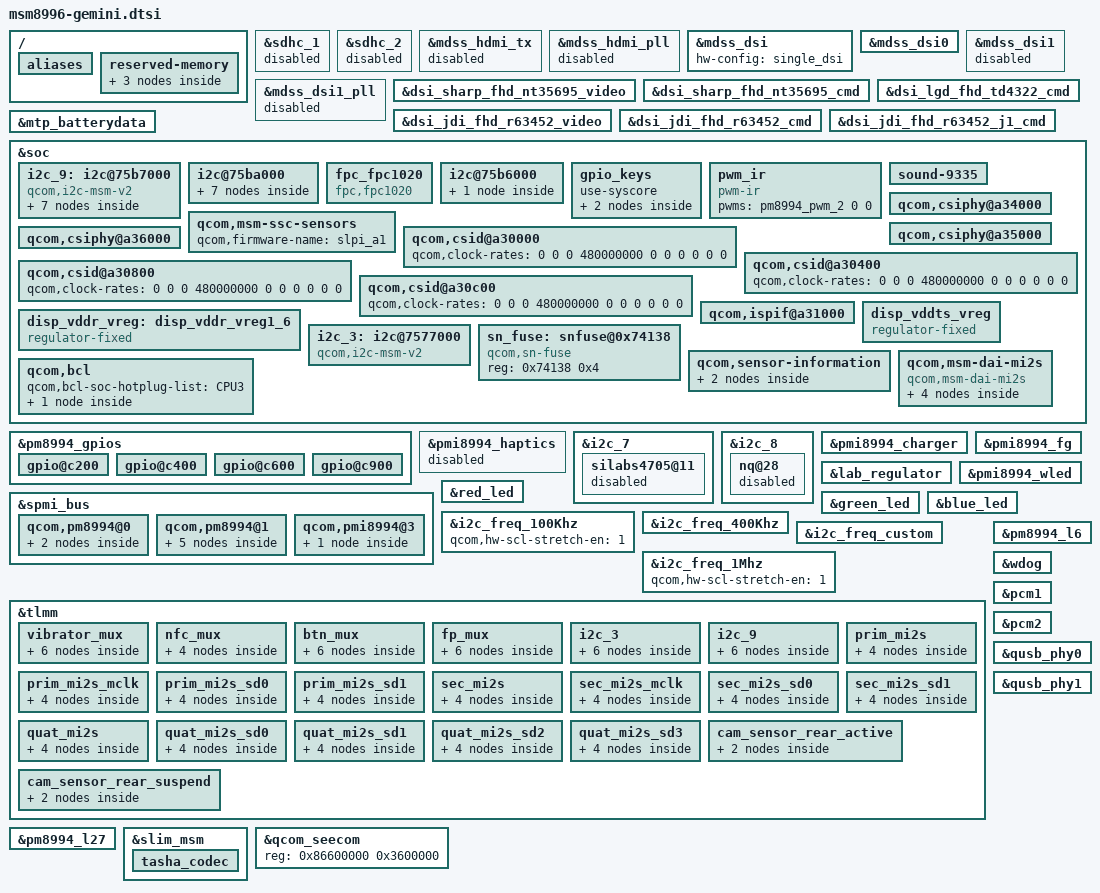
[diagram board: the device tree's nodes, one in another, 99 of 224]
/* Copyright (c) 2015, The Linux Foundation. All rights reserved.
 * Copyright (C) 2016 XiaoMi, Inc.
 *
 * This program is free software; you can redistribute it and/or modify
 * it under the terms of the GNU General Public License version 2 and
 * only version 2 as published by the Free Software Foundation.
 *
 * This program is distributed in the hope that it will be useful,
 * but WITHOUT ANY WARRANTY; without even the implied warranty of
 * MERCHANTABILITY or FITNESS FOR A PARTICULAR PURPOSE.  See the
 * GNU General Public License for more details.
 */

#include "msm8996-mtp.dtsi"
#include "msm8996-camera-sensor-mtp.dtsi"
#include "msm8996-camera-sensor-gemini.dtsi"

// msm8996-mtp.dtsi start
&sdhc_1 {
	status = "disabled";
};

&sdhc_2 {
	status = "disabled";
};

&mdss_hdmi_tx {
	status = "disabled";
};

&mdss_hdmi_pll {
	status = "disabled";
};

#include "msm8996-mdss-panels-gemini.dtsi"

&mdss_dsi {
	hw-config = "single_dsi";
};

&mdss_dsi0 {
	vddr-supply = <&disp_vddr_vreg>;
	qcom,dsi-pref-prim-pan = <&dsi_sharp_fhd_nt35695_video>;
	qcom,platform-enable-gpio = <&tlmm 47 0>;
	qcom,platform-bklight-en-gpio = <&tlmm 48 0>;
};

&mdss_dsi1 {
	status = "disabled";
};

&mdss_dsi1_pll {
	status = "disabled";
};

&dsi_sharp_fhd_nt35695_video {
	qcom,mdss-dsi-bl-pmic-control-type = "bl_ctrl_wled";
	qcom,mdss-dsi-bl-min-level = <1>;
	qcom,mdss-dsi-bl-max-level = <4095>;
	qcom,cont-splash-enabled;
	qcom,panel-supply-entries = <&dsi_panel_pwr_supply>;
};

&dsi_sharp_fhd_nt35695_cmd {
	qcom,mdss-dsi-bl-pmic-control-type = "bl_ctrl_wled";
	qcom,mdss-dsi-bl-min-level = <1>;
	qcom,mdss-dsi-bl-max-level = <4095>;
	qcom,cont-splash-enabled;
	qcom,panel-supply-entries = <&dsi_panel_pwr_supply>;
};

&dsi_lgd_fhd_td4322_cmd {
	qcom,mdss-dsi-bl-pmic-control-type = "bl_ctrl_wled";
	qcom,mdss-dsi-bl-min-level = <1>;
	qcom,mdss-dsi-bl-max-level = <4095>;
	qcom,panel-supply-entries = <&dsi_panel_pwr_supply>;
};

&dsi_jdi_fhd_r63452_video {
	qcom,mdss-dsi-bl-pmic-control-type = "bl_ctrl_wled";
	qcom,mdss-dsi-bl-min-level = <1>;
	qcom,mdss-dsi-bl-max-level = <4095>;
	qcom,cont-splash-enabled;
	qcom,panel-supply-entries = <&dsi_panel_pwr_supply>;
};

&dsi_jdi_fhd_r63452_cmd {
	qcom,mdss-dsi-bl-pmic-control-type = "bl_ctrl_wled";
	qcom,mdss-dsi-bl-min-level = <1>;
	qcom,mdss-dsi-bl-max-level = <4095>;
	qcom,cont-splash-enabled;
	qcom,panel-supply-entries = <&dsi_panel_pwr_supply>;
};

&dsi_jdi_fhd_r63452_j1_cmd {
	qcom,mdss-dsi-bl-pmic-control-type = "bl_ctrl_wled";
	qcom,mdss-dsi-bl-min-level = <1>;
	qcom,mdss-dsi-bl-max-level = <4095>;
	qcom,panel-supply-entries = <&dsi_panel_pwr_supply>;
};

&mtp_batterydata {
	#include "batterydata-a1-atl-3000mah.dtsi"
	#include "batterydata-a1-sdi-3000mah.dtsi"
};

&soc {
	i2c@75b7000 {
		status = "ok";

		tfa98xx@34 {
			reg = <0x34>;
			compatible = "nxp,tfa9890";
			nxp,reset-gpio = <&pmi8994_gpios 2 0>;
		};

		drv2604@5a {
			compatible = "vibrator,drv2604";
			reg = <0x5a>;
			qcom,vibrator-gpio = <&tlmm 93 0x00>;
			pinctrl-names = "vibrator_active","vibrator_suspend";
			pinctrl-0 = <&vibrator_active>;
			pinctrl-1 = <&vibrator_suspend>;
		};

		lp5562@30 {
			compatible = "ti,lp5562";
			reg = <0x30>;
			enable-gpio = <&pm8994_gpios 7 1>;
			clock-mode = /bits/8 <2>;
			label = "button-backlight";
			chan0 {
				chan-name = "button-backlight";
				led-cur = /bits/ 8 <0x32>;
				max-cur = /bits/ 8 <0xC8>;
			};
			chan1 {
				chan-name = "button-backlight1";
				led-cur = /bits/ 8 <0x32>;
				max-cur = /bits/ 8 <0xC8>;
			};
		};

		tusb320l@67 {
			compatible = "ti,tusb320l";
			reg = <0x67>;
		};

		tusb320l@47 {
			compatible = "ti,tusb320l";
			reg = <0x47>;
		};
	};

	i2c@75ba000 {
		/delete-node/ synaptics@20;

		synaptics_dsi_i2c@20 {
			compatible = "synaptics,dsx-i2c";
			reg = <0x20>;
			interrupt-parent = <&tlmm>;
			interrupts = <125 0x2008>;
			vdd-supply = <&pm8994_l6>;
			lab-supply = <&lab_regulator>;
			ibb-supply = <&ibb_regulator>;
			disp-supply = <&pm8994_l14>;
			avdd-supply = <&disp_vddts_vreg>;
			synaptics,pwr-reg-name = "vdd";
			synaptics,lab-reg-name = "lab";
			synaptics,ibb-reg-name = "ibb";
			synaptics,disp-reg-name = "disp";
			synaptics,bus-reg-name = "avdd";
			synaptics,ub-i2c-addr = <0x20>;
			pinctrl-names = "pmx_ts_active", "pmx_ts_suspend";
			pinctrl-0 = <&ts_active>;
			pinctrl-1 = <&ts_suspend>;
			synaptics,mdss-dsi-reset = <&tlmm 8 0>;
			synaptics,reset-gpio = <&tlmm 89 0x00>;
			synaptics,irq-gpio = <&tlmm 125 0x2008>;
			synaptics,reset-gpio-name = "dsx_reset";
			synaptics,irq-gpio-name = "dsx_irq";
			synaptics,irq-on-state = <0>;
			synaptics,irq-flags = <0x2008>; /* IRQF_ONESHOT | IRQF_TRIGGER_LOW */
			synaptics,power-delay-ms = <5>;
			synaptics,reset-delay-ms = <200>;
			synaptics,reset-active-ms = <5>;
			synaptics,power-on-state = <1>;
			synaptics,reset-on-state = <0>;
			synaptics,mdss-reset-state = <1>;
			synaptics,cap-button-codes = <158 139 102>;
			clock-names = "iface_clk", "core_clk";
			clocks = <&clock_gcc clk_gcc_blsp2_ahb_clk>,
				<&clock_gcc clk_gcc_blsp2_qup6_i2c_apps_clk>;
			synaptics,guest-serialization-as-lockdown;
			synaptics,tp-id-byte = /bits/ 8 <0>;
		};

		atmel_mxt_ts_641t@4a {
			compatible = "atmel,mxt-ts";
			reg = <0x4a>;
			interrupt-parent = <&tlmm>;
			interrupts = <125 0x2008>;
			vddio-supply = <&pm8994_l6>;
			vdd-supply = <&disp_vddts_vreg>;
			/* pins used by touchscreen */
			pinctrl-names = "pmx_ts_active","pmx_ts_suspend";
			pinctrl-0 = <&ts_active>;
			pinctrl-1 = <&ts_suspend>;
			atmel,reset-gpio = <&tlmm 89 0x00>;
			atmel,irq-gpio = <&tlmm 125 0x2008>;
			atmel,mxt-fw-name = "mXT641T30AC.fw";
			atmel,config-array-size = <5>;
			atmel,default-config = <0>;
			atmel,default-panel-id = <0x31>;
			atmel,irqflags = <0x2008>;
			atmel,gpio-mask = <0xC>;
			atmel,cfg_1 {
				atmel,family-id = <0xA4>;
				atmel,variant-id = <0x2F>;
				atmel,version = <0x30>;
				atmel,build = <0xAC>;
				atmel,rev-id = <0x32>;
				atmel,mxt-cfg-name = "mxt_641t_sharp_config.fw";
				atmel,vendor-id = <0x0C>;
				atmel,panel-id = <0x38>; /* Sharp id = 0x38 */
				atmel,key-codes = <158 139 102>;
				atmel,selfintthr-stylus = <0>;
				atmel,t71-tchthr-pos = <22>;
				atmel,self-chgtime-min = <0>;
				atmel,self-chgtime-max = <0>;
				atmel,mult-intthr-sensitive = <0>;
				atmel,mult-intthr-not-sensitive = <17>;
				atmel,atchthr-sensitive = <6>;
				atmel,mult-tchthr-sensitive = <0x0f>;
				atmel,mult-tchthr-not-sensitive = <0>;
				atmel,wake-up-self-adcx = <16>;
				atmel,atchratio = <33>;
				atmel,xycfg = <0>;
				atmel,xsize = <0x07>;
				atmel,xrange-lsb = <0x08>;
				atmel,xrange-msb = <0x02>;
				atmel,tchhyst = <0x05>;
				atmel,intthrhyst = <0>;
				atmel,xtchthr = <0x0f>;
				atmel,xtchhyst = <0x05>;
				atmel,intthrx = <0>;
				atmel,ytchthr = <0x0f>;
				atmel,ytchhyst = <0x05>;
				atmel,intthry = <0>;
			};
			atmel,cfg_2 {
				atmel,family-id = <0xA4>;
				atmel,variant-id = <0x2F>;
				atmel,version = <0x30>;
				atmel,build = <0xAC>;
				atmel,rev-id = <0x32>;
				atmel,mxt-cfg-name = "mxt_641t_sharp_config.fw";
				atmel,vendor-id = <0x0C>;
				atmel,panel-id = <0x31>; /* Biel id = 0x31 */
				atmel,key-codes = <158 139 102>;
				atmel,selfintthr-stylus = <0>;
				atmel,t71-tchthr-pos = <22>;
				atmel,self-chgtime-min = <0>;
				atmel,self-chgtime-max = <0>;
				atmel,mult-intthr-sensitive = <0>;
				atmel,mult-intthr-not-sensitive = <17>;
				atmel,atchthr-sensitive = <6>;
				atmel,mult-tchthr-sensitive = <0x0f>;
				atmel,mult-tchthr-not-sensitive = <0>;
				atmel,wake-up-self-adcx = <16>;
				atmel,atchratio = <33>;
				atmel,xycfg = <0>;
				atmel,xsize = <0x07>;
				atmel,xrange-lsb = <0x08>;
				atmel,xrange-msb = <0x02>;
				atmel,tchhyst = <0x05>;
				atmel,intthrhyst = <0>;
				atmel,xtchthr = <0x0f>;
				atmel,xtchhyst = <0x05>;
				atmel,intthrx = <0>;
				atmel,ytchthr = <0x0f>;
				atmel,ytchhyst = <0x05>;
				atmel,intthry = <0>;
			};
			atmel,cfg_3 {
				atmel,family-id = <0xA4>;
				atmel,variant-id = <0x2F>;
				atmel,version = <0x30>;
				atmel,build = <0xAC>;
				atmel,rev-id = <0x32>;
				atmel,mxt-cfg-name = "mxt_641t_sharp_config.fw";
				atmel,vendor-id = <0x0C>;
				atmel,panel-id = <0x51>; /* WA: Incorrect lockdown */
				atmel,key-codes = <158 139 102>;
				atmel,selfintthr-stylus = <0>;
				atmel,t71-tchthr-pos = <22>;
				atmel,self-chgtime-min = <0>;
				atmel,self-chgtime-max = <0>;
				atmel,mult-intthr-sensitive = <0>;
				atmel,mult-intthr-not-sensitive = <17>;
				atmel,atchthr-sensitive = <6>;
				atmel,mult-tchthr-sensitive = <0x0f>;
				atmel,mult-tchthr-not-sensitive = <0>;
				atmel,wake-up-self-adcx = <16>;
				atmel,atchratio = <33>;
				atmel,xycfg = <0>;
				atmel,xsize = <0x07>;
				atmel,xrange-lsb = <0x08>;
				atmel,xrange-msb = <0x02>;
				atmel,tchhyst = <0x05>;
				atmel,intthrhyst = <0>;
				atmel,xtchthr = <0x0f>;
				atmel,xtchhyst = <0x05>;
				atmel,intthrx = <0>;
				atmel,ytchthr = <0x0f>;
				atmel,ytchhyst = <0x05>;
				atmel,intthry = <0>;
			};
			atmel,cfg_4 {
				atmel,family-id = <0xA4>;
				atmel,variant-id = <0x2F>;
				atmel,version = <0x30>;
				atmel,build = <0xAC>;
				atmel,rev-id = <0x32>;
				atmel,mxt-cfg-name = "mxt_641t_sharp_config.fw";
				atmel,vendor-id = <0x0C>;
				atmel,panel-id = <0x52>; /* WA: Incorrect lockdown */
				atmel,key-codes = <158 139 102>;
				atmel,selfintthr-stylus = <0>;
				atmel,t71-tchthr-pos = <22>;
				atmel,self-chgtime-min = <0>;
				atmel,self-chgtime-max = <0>;
				atmel,mult-intthr-sensitive = <0>;
				atmel,mult-intthr-not-sensitive = <17>;
				atmel,atchthr-sensitive = <6>;
				atmel,mult-tchthr-sensitive = <0x0f>;
				atmel,mult-tchthr-not-sensitive = <0>;
				atmel,wake-up-self-adcx = <16>;
				atmel,atchratio = <33>;
				atmel,xycfg = <0>;
				atmel,xsize = <0x07>;
				atmel,xrange-lsb = <0x08>;
				atmel,xrange-msb = <0x02>;
				atmel,tchhyst = <0x05>;
				atmel,intthrhyst = <0>;
				atmel,xtchthr = <0x0f>;
				atmel,xtchhyst = <0x05>;
				atmel,intthrx = <0>;
				atmel,ytchthr = <0x0f>;
				atmel,ytchhyst = <0x05>;
				atmel,intthry = <0>;
			};
			atmel,cfg_5 {
				atmel,family-id = <0xA4>;
				atmel,variant-id = <0x2F>;
				atmel,version = <0x30>;
				atmel,build = <0xAC>;
				atmel,rev-id = <0x32>;
				atmel,mxt-cfg-name = "mxt_641t_sharp_config.fw";
				atmel,vendor-id = <0x0C>;
				atmel,panel-id = <0x32>; /* lens id = 0x32 */
				atmel,key-codes = <158 139 102>;
				atmel,selfintthr-stylus = <0>;
				atmel,t71-tchthr-pos = <22>;
				atmel,self-chgtime-min = <0>;
				atmel,self-chgtime-max = <0>;
				atmel,mult-intthr-sensitive = <0>;
				atmel,mult-intthr-not-sensitive = <17>;
				atmel,atchthr-sensitive = <6>;
				atmel,mult-tchthr-sensitive = <0x0f>;
				atmel,mult-tchthr-not-sensitive = <0>;
				atmel,wake-up-self-adcx = <16>;
				atmel,atchratio = <33>;
				atmel,xycfg = <0>;
				atmel,xsize = <0x07>;
				atmel,xrange-lsb = <0x08>;
				atmel,xrange-msb = <0x02>;
				atmel,tchhyst = <0x05>;
				atmel,intthrhyst = <0>;
				atmel,xtchthr = <0x0f>;
				atmel,xtchhyst = <0x05>;
				atmel,intthrx = <0>;
				atmel,ytchthr = <0x0f>;
				atmel,ytchhyst = <0x05>;
				atmel,intthry = <0>;
			};
		};
	};

	fpc_fpc1020 {
		compatible = "fpc,fpc1020";
		fpc,reset-gpio	= <&tlmm 50 0x00>;
		fpc,irq-gpio	= <&tlmm 121 0x2001>;
		fpc,fp-id-gpio = <&pm8994_gpios 10 0x00>;
		pinctrl-names = "pmx_fp_active", "pmx_fp_suspend";
		pinctrl-0 = <&fp_active>;
		pinctrl-1 = <&fp_suspend>;
		vcc_spi-supply	= <&pm8994_s4>;
		vdd_ana-supply	= <&pm8994_s4>;
		vdd_io-supply	= <&pm8994_s4>;
	};

	i2c@75b6000 {
		pn548 {
			compatible = "nxp,nfc-548";
			reg = <0x28>;
			nxp-nfc-548,irq-gpio = <&tlmm 9 0x00>;
			nxp-nfc-548,firm-gpio = <&tlmm 21 0x00>;
			nxp-nfc-548,ven-gpio = <&tlmm 12 0x00>;
			interrupt-parent = <&tlmm>;
			interrupts = <9 0>;
			interrupt-names = "nfc_irq";
			pinctrl-names = "pmx_nfc_active","pmx_nfc_suspend";
			pinctrl-0 = <&nfc_active>;
			pinctrl-1 = <&nfc_suspend>;
		};
	};

	gpio_keys {
		use-syscore;

		dome {
			label = "dome";
			gpios = <&tlmm 34 0x1>;
			linux,input-type = <1>;
			linux,code = <102>;
			gpio-key,wakeup;
			debounce-interval = <15>;
		};

		/delete-node/ cam_focus;

		hall_key0 {
			label = "hall_key0";
			gpios = <&tlmm 124 0x01>;
			linux,input-type = <5>;
			linux,code = <0>;
			gpio-key,wakeup;
			debounce-interval = <15>;
		};
	};

	pwm_ir {
		compatible = "pwm-ir";
		pwms = <&pm8994_pwm_2 0 0>;
	};

	sound-9335 {
		qcom,audio-routing =
			"AIF4 VI", "MCLK",
			"RX_BIAS", "MCLK",
			"MADINPUT", "MCLK",
			"hifi amp", "LINEOUT1",
			"hifi amp", "LINEOUT2",
			"AMIC1", "MIC BIAS1",
			"MIC BIAS1", "Handset Mic",
			"AMIC2", "MIC BIAS2",
			"MIC BIAS2", "Headset Mic",
			"AMIC3", "MIC BIAS4",
			"MIC BIAS4", "ANCRight Headset Mic",
			"AMIC4", "MIC BIAS4",
			"MIC BIAS4", "ANCLeft Headset Mic",
			"AMIC5", "MIC BIAS3",
			"MIC BIAS3", "Handset Mic",
			"AMIC6", "MIC BIAS4",
			"MIC BIAS4", "Analog Mic6",
			"DMIC0", "MIC BIAS1",
			"MIC BIAS1", "Digital Mic0",
			"DMIC1", "MIC BIAS1",
			"MIC BIAS1", "Digital Mic1",
			"DMIC2", "MIC BIAS3",
			"MIC BIAS3", "Digital Mic2",
			"DMIC3", "MIC BIAS3",
			"MIC BIAS3", "Digital Mic3",
			"DMIC4", "MIC BIAS4",
			"MIC BIAS4", "Digital Mic4",
			"DMIC5", "MIC BIAS4",
			"MIC BIAS4", "Digital Mic5",
			"SpkrLeft IN", "SPK1 OUT",
			"SpkrRight IN", "SPK2 OUT";

		qcom,msm-mbhc-hphl-swh = <1>;
		qcom,msm-mbhc-gnd-swh = <1>;

		/delete-property/ qcom,hdmi-audio-rx;

		asoc-cpu = <&dai_pri_auxpcm>, <&dai_sec_auxpcm>, <&dai_hdmi>,
				<&dai_pri_mi2s>, <&dai_sec_mi2s>,
				<&dai_tert_mi2s>, <&dai_quat_mi2s>,
				<&sb_0_rx>, <&sb_0_tx>, <&sb_1_rx>, <&sb_1_tx>,
				<&sb_2_rx>, <&sb_2_tx>, <&sb_3_rx>, <&sb_3_tx>,
				<&sb_4_rx>, <&sb_4_tx>, <&sb_5_tx>, <&afe_pcm_rx>,
				<&afe_pcm_tx>, <&afe_proxy_rx>, <&afe_proxy_tx>,
				<&incall_record_rx>, <&incall_record_tx>,
				<&incall_music_rx>, <&incall_music2_rx>,
				<&sb_5_rx>, <&sb_6_rx>;
		asoc-cpu-names = "msm-dai-q6-auxpcm.1", "msm-dai-q6-auxpcm.2",
				"msm-dai-q6-hdmi.8", "msm-dai-q6-mi2s.0",
				"msm-dai-q6-mi2s.1", "msm-dai-q6-mi2s.2",
				"msm-dai-q6-mi2s.3",
				"msm-dai-q6-dev.16384", "msm-dai-q6-dev.16385",
				"msm-dai-q6-dev.16386", "msm-dai-q6-dev.16387",
				"msm-dai-q6-dev.16388", "msm-dai-q6-dev.16389",
				"msm-dai-q6-dev.16390", "msm-dai-q6-dev.16391",
				"msm-dai-q6-dev.16392", "msm-dai-q6-dev.16393",
				"msm-dai-q6-dev.16395", "msm-dai-q6-dev.224",
				"msm-dai-q6-dev.225", "msm-dai-q6-dev.241",
				"msm-dai-q6-dev.240", "msm-dai-q6-dev.32771",
				"msm-dai-q6-dev.32772", "msm-dai-q6-dev.32773",
				"msm-dai-q6-dev.32770", "msm-dai-q6-dev.16394",
				"msm-dai-q6-dev.16396";
		asoc-codec = <&stub_codec>;
		asoc-codec-names = "msm-stub-codec.1", "msm-hdmi-audio-codec-rx";

		/delete-property/ qcom,hph-en1-gpio;
		/delete-property/ qcom,hph-en0-gpio;
		/delete-property/ qcom,us-euro-gpios;
		/delete-property/ qcom,wsa-max-devs;
		/delete-property/ qcom,wsa-devs;
		/delete-property/ qcom,wsa-aux-dev-prefix;

		spkr-id-gpio = <&pm8994_gpios 3 0>;
	};

	qcom,msm-ssc-sensors {
		qcom,firmware-name = "slpi_a1";
	};
};

&pm8994_gpios {
	gpio@c200 { /* GPIO 3 */
		qcom,mode = <0>;
		qcom,pull = <0>;
		qcom,vin-sel = <2>;
		qcom,src-sel = <0>;
		qcom,master-en = <0>;
		status = "okay";
	};

	gpio@c400 { /* GPIO 5 - INFARED_DRV */
		qcom,mode = <1>;		/* QPNP_PIN_MODE_DIG_OUT */
		qcom,output-type = <0>;		/* QPNP_PIN_OUT_BUF_CMOS */
		qcom,invert = <0>;		/* QPNP_PIN_INVERT_DISABLE */
		qcom,out-strength = <3>;	/* QPNP_PIN_OUT_STRENGTH_HIGH */
		qcom,vin-sel = <2>;		/* Logical 1 voltage value 1.8v */
		qcom,src-sel = <2>;		/* QPNP_PIN_SEL_FUNC_2(LPG) */
		qcom,master-en = <1>;		/* QPNP_PIN_MASTER_ENABLE */
		/delete-property/ qcom,pull;
		status = "okay";
	};

	gpio@c600 { /* GPIO 7 - KEYPAD_LED_EN */
		qcom,mode = <1>;		/* DIGITAL OUT */
		qcom,output-type = <0>;		/* CMOS logic */
		qcom,invert = <1>;		/* output hight initially */
		qcom,vin-sel = <2>;		/* 1.8 */
		qcom,src-sel = <0>;		/* CONSTANT */
		qcom,out-strength = <1>;	/* Low drive strength */
		qcom,master-en = <1>;		/* ENABLE GPIO */
		/delete-property/ qcom,pull;
		status = "okay";
	};

	gpio@c900 { /* GPIO 10 - FPC fingerprint ID detect */
		qcom,mode = <0>;
		qcom,pull = <0>;
		qcom,vin-sel = <2>;
		qcom,src-sel = <0>;
		qcom,master-en = <1>;
		status = "okay";
	};
};

&pmi8994_haptics {
	status = "disabled";
};

&i2c_7 {
	silabs4705@11 {
		status = "disabled";
	};
};

&i2c_8 {
	nq@28 {
		status = "disabled";
	};
};
// msm8996-mtp.dtsi end

// msm-pm8994.dtsi start
&spmi_bus {
	qcom,pm8994@0 {
		qcom,power-on@800 {
			qcom,s3-debounce = <32>;
			qcom,s3-src = "kpdpwr-and-resin";

			qcom,pon_1 {
				qcom,s1-timer = <4480>;
				qcom,s2-type = <7>;
			};
		};
	};

	qcom,pm8994@1 {
		pm8994_pwm_1: pwm@b100 {
			qcom,supported-sizes = <6>, <9>;
			status = "okay";
		};

		pm8994_pwm_2: pwm@b200 {
			status = "okay";
		};

		pm8994_pwm_3: pwm@b300 {
			status = "okay";
		};

		pm8994_pwm_4: pwm@b400 {
			status = "okay";
		};

		pm8994_pwm_6: pwm@b600 {
			status = "okay";
		};
	};
};
// msm-pm8994.dtsi end

// msm-pmi8994.dtsi start
&pmi8994_charger {
	qcom,fastchg-current-ma = <3000>;
	qcom,float-voltage-mv = <4400>;
	qcom,thermal-mitigation = <2500 2000 1500 1000>;
	qcom,fastchg-current-comp = <1200>;
	qcom,float-voltage-comp = <16>;
	qcom,override-usb-current;
};

&pmi8994_fg {
	qcom,resume-soc = <99>;
	qcom,fg-iterm-ma = <200>;
	fg-cutoff-voltage-mv = <3400>;
	qcom,thermal-coefficients = [DA 86 F0 50 08 3C];
	qcom,vbat-estimate-diff-mv = <300>;

	qcom,warm-bat-decidegc = <450>;
	qcom,cool-bat-decidegc = <100>;
	qcom,hot-bat-decidegc  = <600>;
	qcom,cold-bat-decidegc = <0>;
	/delete-property/ qcom,fg-cc-cv-threshold-mv;
};

&lab_regulator {
	qcom,qpnp-lab-soft-start = <400>;

	qcom,qpnp-lab-ps-threshold = <30>;
};

&pmi8994_wled {
	qcom,switch-freq-khz = <600>;
	qcom,fs-curr-ua = <20000>;
	qcom,en-cabc;
	qcom,en-phase-stag;
	qcom,led-strings-list = [00 01];
};

&spmi_bus {
	qcom,pmi8994@3 {
		qcom,leds@d000 {
			qcom,rgb-sync;
		};
	};
};

&red_led {
	/delete-property/ linux,default-trigger;
	qcom,duty-pcts = [ 00 0E 1C 2A 38 46 54 64 ];
	qcom,start-idx = <0>;
	qcom,idx-len = <8>;
	qcom,pause-lo = <500>;
	qcom,pause-hi = <500>;
	qcom,ramp-step-ms = <50>;
	qcom,lut-flags = <31>; /* loop, ramp up, reverse, pause hi, pause lo */
	qcom,use-blink;
};

&green_led {
	/delete-property/ linux,default-trigger;
	qcom,duty-pcts = [ 00 0E 1C 2A 38 46 54 64 ];
	qcom,start-idx = <8>;
	qcom,idx-len = <8>;
	qcom,pause-lo = <500>;
	qcom,pause-hi = <500>;
	qcom,ramp-step-ms = <50>;
	qcom,lut-flags = <31>; /* loop, ramp up, reverse, pause hi, pause lo */
	qcom,use-blink;
};

&blue_led {
	/delete-property/ linux,default-trigger;
	qcom,duty-pcts = [ 00 0E 1C 2A 38 46 54 64 ];
	qcom,start-idx = <16>;
	qcom,idx-len = <8>;
	qcom,pause-lo = <500>;
	qcom,pause-hi = <500>;
	qcom,ramp-step-ms = <50>;
	qcom,lut-flags = <31>; /* loop, ramp up, reverse, pause hi, pause lo */
	qcom,use-blink;
};
// msm-pmi8994.dtsi end

// msm8996-camera.dtsi start
&soc {
	qcom,csiphy@a34000 {
		qcom,clock-rates = <0 0 266670000 0 0 320000000 0>;
	};

	qcom,csiphy@a35000 {
		qcom,clock-rates = <0 0 266670000 0 0 320000000 0>;
	};

	qcom,csiphy@a36000 {
		qcom,clock-rates = <0 0 266670000 0 0 320000000 0>;
	};

	qcom,csid@a30000 {
		qcom,clock-rates = <0 0 0 480000000 0 0 0 0 0 0>;
	};

	qcom,csid@a30400 {
		qcom,clock-rates = <0 0 0 480000000 0 0 0 0 0 0>;
	};

	qcom,csid@a30800 {
		qcom,clock-rates = <0 0 0 480000000 0 0 0 0 0 0>;
	};

	qcom,csid@a30c00 {
		qcom,clock-rates = <0 0 0 480000000 0 0 0 0 0 0>;
	};

	qcom,ispif@a31000 {
		qcom,clock-rates = <0 0 0 0
			480000000 0 0 0
			480000000 0 0 0
			480000000 0 0 0
			480000000 0 0 0
			0 0 0
			0 0 0>;
	};
};

&i2c_freq_100Khz {
	qcom,hw-scl-stretch-en = <1>;
};

&i2c_freq_400Khz {
	qcom,hw-tlow = <55>;
	qcom,hw-scl-stretch-en = <1>;
};

&i2c_freq_custom {
	qcom,hw-thigh = <38>;
	qcom,hw-tlow = <56>;
	qcom,hw-tsu-sto = <40>;
	qcom,hw-tsu-sta = <40>;
	qcom,hw-thd-dat = <22>;
	qcom,hw-thd-sta = <35>;
	qcom,hw-tbuf = <62>;
};

&i2c_freq_1Mhz {
	qcom,hw-scl-stretch-en = <1>;
};
// msm8996-camera.dtsi end

// msm8996-pinctrl.dtsi start
&tlmm {
	vibrator_mux {
		vibrator_active: vibrator_active {
			mux {
				pins = "gpio93";
				function = "gpio";
			};

			config {
				pins = "gpio93";
				drive-strength = <8>;
				bias-pull-up;
			};
		};

		vibrator_suspend: vibrator_suspend {
			mux {
				pins = "gpio93";
				function = "gpio";
			};

			config {
				pins = "gpio93";
				drive-strength = <2>;
				bias-disable;
			};
		};
	};

	nfc_mux {
		nfc_active: nfc_active {
			nfc_mux {
				pins = "gpio12", "gpio21";
				drive-strength = <16>;
				bias-pull-up;
			};
		};

		nfc_suspend: nfc_suspend {
			nfc_mux {
				pins = "gpio12", "gpio21";
				drive-strength = <2>;
				bias-disable;
			};
		};
	};

	btn_mux {
		btn_active: btn_active {
			mux {
				pins = "gpio78";
				function = "gpio";
			};

			config {
				pins = "gpio78";
				drive-strength = <16>;
				bias-pull-up;
			};
		};

		btn_suspend: btn_suspend {
			mux {
				pins = "gpio78";
				function = "gpio";
			};

			config {
				pins = "gpio78";
				drive-strength = <2>;
				bias-disable;
			};
		};
	};

	fp_mux {
		fp_active: fp_active {
			mux {
				pins = "gpio50", "gpio121";
				function = "gpio";
			};

			config {
				pins = "gpio50", "gpio121";
				drive-strength = <8>;
				bias-disable;
			};
		};

		fp_suspend: fp_suspend {
			mux {
				pins = "gpio50", "gpio121";
				function = "gpio";
			};
			config {
				pins = "gpio50", "gpio121";
				drive-strength = <2>;
				bias-disable;
			};
		};
	};

	i2c_3 {
		i2c_3_active: i2c_3_active {
			mux {
				pins = "gpio47", "gpio48";
				function = "blsp_i2c3";
			};

			config {
				pins = "gpio47", "gpio48";
				drive-strength = <2>;
				bias-disable;
			};
		};

		i2c_3_sleep: i2c_3_sleep {
			mux {
				pins = "gpio47", "gpio48";
				function = "blsp_i2c3";
			};

			config {
				pins = "gpio47", "gpio48";
				drive-strength = <2>;
				bias-pull-up;
			};
		};
	};

	i2c_9 {
		i2c_9_active: i2c_9_active {
			mux {
				pins = "gpio51", "gpio52";
				function = "blsp_i2c9";
			};

			config {
				pins = "gpio51", "gpio52";
				driver-strength = <2>;
				bias-disable;
			};
		};

		i2c_9_sleep: i2c_9_sleep {
			mux {
				pins = "gpio51", "gpio52";
				function = "blsp_i2c9";
			};

			config {
				pins = "gpio51", "gpio52";
				drive-strength = <2>;
				bias-pull-up;
			};
		};
	};

	prim_mi2s {
		pri_mi2s_sleep: pri_mi2s_sleep {
			prim_mi2s {
				pins = "gpio65", "gpio66";
				function = "pri_mi2s";
				drive-strength = <2>;   /* 2 mA */
				bias-pull-down;         /* PULL DOWN */
			};
		};
		pri_mi2s_active: pri_mi2s_active {
			prim_mi2s {
				pins = "gpio65", "gpio66";
				function = "pri_mi2s";
				drive-strength = <8>;   /* 8 mA */
				bias-disable;           /* NO PULL */
				output-high;
			};
		};
	};

	prim_mi2s_mclk {
		pri_mi2s_mclk_sleep: pri_mi2s_mclk_sleep {
			prim_mi2s {
				pins = "gpio64";
				function = "pri_mi2s";
				drive-strength = <2>;   /* 2 mA */
				bias-pull-down;         /* PULL DOWN */
			};
		};
		pri_mi2s_mclk_active: pri_mi2s_mclk_active {
			prim_mi2s {
				pins = "gpio64";
				function = "pri_mi2s";
				drive-strength = <8>;   /* 8 mA */
				bias-disable;           /* NO PULL */
				output-high;
			};
		};
	};

	prim_mi2s_sd0 {
		pri_mi2s_sd0_sleep: pri_mi2s_sd0_sleep {
			prim_mi2s_sd0 {
				pins = "gpio67";
				function = "pri_mi2s";
				drive-strength = <2>;   /* 2 mA */
				bias-pull-down;         /* PULL DOWN */
			};
		};
		pri_mi2s_sd0_active: pri_mi2s_sd0_active {
			prim_mi2s_sd0 {
				pins = "gpio67";
				function = "pri_mi2s";
				drive-strength = <8>;   /* 8 mA */
				bias-disable;           /* NO PULL */
			};
		};
	};

	prim_mi2s_sd1 {
		pri_mi2s_sd1_sleep: pri_mi2s_sd1_sleep {
			prim_mi2s_sd1 {
				pins = "gpio68";
				function = "pri_mi2s";
				drive-strength = <2>;   /* 2 mA */
				bias-pull-down;         /* PULL DOWN */
			};
		};
		pri_mi2s_sd1_active: pri_mi2s_sd1_active {
			prim_mi2s_sd1 {
				pins = "gpio68";
				function = "pri_mi2s";
				drive-strength = <8>;   /* 8 mA */
				bias-disable;           /* NO PULL */
			};
		};
	};

	sec_mi2s {
		sec_mi2s_sleep: sec_mi2s_sleep {
			sec_mi2s {
				pins = "gpio80", "gpio81";
				function = "sec_mi2s";
				drive-strength = <2>;   /* 2 mA */
				bias-pull-down;         /* PULL DOWN */
			};
		};
		sec_mi2s_active: sec_mi2s_active {
			sec_mi2s {
				pins = "gpio80", "gpio81";
				function = "sec_mi2s";
				drive-strength = <8>;   /* 8 mA */
				bias-disable;           /* NO PULL */
				output-high;
			};
		};
	};

	sec_mi2s_mclk {
		sec_mi2s_mclk_sleep: sec_mi2s_mclk_sleep {
			sec_mi2s {
				pins = "gpio79";
				function = "sec_mi2s";
				drive-strength = <2>;   /* 2 mA */
				bias-pull-down;         /* PULL DOWN */
			};
		};
		sec_mi2s_mclk_active: sec_mi2s_mclk_active {
			sec_mi2s {
				pins = "gpio79";
				function = "sec_mi2s";
				drive-strength = <8>;   /* 8 mA */
				bias-disable;           /* NO PULL */
				output-high;
			};
		};
	};

	sec_mi2s_sd0 {
		sec_mi2s_sd0_sleep: sec_mi2s_sd0_sleep {
			sec_mi2s_sd0 {
				pins = "gpio82";
				function = "sec_mi2s";
				drive-strength = <2>;   /* 2 mA */
				bias-pull-down;         /* PULL DOWN */
			};
		};
		sec_mi2s_sd0_active: sec_mi2s_sd0_active {
			sec_mi2s_sd0 {
				pins = "gpio82";
				function = "sec_mi2s";
				drive-strength = <8>;   /* 8 mA */
				bias-disable;           /* NO PULL */
			};
		};
	};

	sec_mi2s_sd1 {
		sec_mi2s_sd1_sleep: sec_mi2s_sd1_sleep {
			sec_mi2s_sd1 {
				pins = "gpio83";
				function = "sec_mi2s";
				drive-strength = <2>;   /* 2 mA */
				bias-pull-down;         /* PULL DOWN */
			};
		};
		sec_mi2s_sd1_active: sec_mi2s_sd1_active {
			sec_mi2s_sd1 {
				pins = "gpio83";
				function = "sec_mi2s";
				drive-strength = <8>;   /* 8 mA */
				bias-disable;           /* NO PULL */
			};
		};
	};

	/delete-node/ quat_mi2s;
	quat_mi2s {
		quat_mi2s_sleep: quat_mi2s_sleep {
			quat_mi2s {
				pins = "gpio58", "gpio59";
				function = "qua_mi2s";
				drive-strength = <2>;   /* 2 mA */
				bias-pull-down;         /* PULL DOWN */
			};
		};
		quat_mi2s_active: quat_mi2s_active {
			quat_mi2s {
				pins = "gpio58", "gpio59";
				function = "qua_mi2s";
				drive-strength = <8>;   /* 8 mA */
				bias-disable;           /* NO PULL */
				output-high;
			};
		};
	};

	/delete-node/ quat_mi2s_sd0;
	quat_mi2s_sd0 {
		quat_mi2s_sd0_sleep: quat_mi2s_sd0_sleep {
			quat_mi2s_sd0 {
				pins = "gpio60";
				function = "qua_mi2s";
				drive-strength = <2>;   /* 2 mA */
				bias-pull-down;         /* PULL DOWN */
			};
		};
		quat_mi2s_sd0_active: quat_mi2s_sd0_active {
			quat_mi2s_sd0 {
				pins = "gpio60";
				function = "qua_mi2s";
				drive-strength = <8>;   /* 8 mA */
				bias-disable;           /* NO PULL */
			};
		};
	};

	quat_mi2s_sd1 {
		quat_mi2s_sd1_sleep: quat_mi2s_sd1_sleep {
			quat_mi2s_sd1 {
				pins = "gpio61";
				function = "qua_mi2s";
				drive-strength = <2>;   /* 2 mA */
				bias-pull-down;         /* PULL DOWN */
			};
		};
		quat_mi2s_sd1_active: quat_mi2s_sd1_active {
			quat_mi2s_sd1 {
				pins = "gpio61";
				function = "qua_mi2s";
				drive-strength = <8>;   /* 8 mA */
				bias-disable;           /* NO PULL */
			};
		};
	};

	quat_mi2s_sd2 {
		quat_mi2s_sd2_sleep: quat_mi2s_sd2_sleep {
			quat_mi2s_sd2 {
				pins = "gpio62";
				function = "qua_mi2s";
				drive-strength = <2>;   /* 2 mA */
				bias-pull-down;         /* PULL DOWN */
			};
		};
		quat_mi2s_sd2_active: quat_mi2s_sd2_active {
			quat_mi2s_sd2 {
				pins = "gpio62";
				function = "qua_mi2s";
				drive-strength = <8>;   /* 8 mA */
				bias-disable;           /* NO PULL */
			};
		};
	};

	quat_mi2s_sd3 {
		quat_mi2s_sd3_sleep: quat_mi2s_sd3_sleep {
			quat_mi2s_sd3 {
				pins = "gpio63";
				function = "qua_mi2s";
				drive-strength = <2>;   /* 2 mA */
				bias-pull-down;         /* PULL DOWN */
			};
		};
		quat_mi2s_sd3_active: quat_mi2s_sd3_active {
			quat_mi2s_sd3 {
				pins = "gpio63";
				function = "qua_mi2s";
				drive-strength = <8>;   /* 8 mA */
				bias-disable;           /* NO PULL */
			};
		};
	};

	cam_sensor_rear_active: cam_sensor_rear_active {
		mux {
			pins = "gpio86", "gpio30";
		};

		config {
			pins = "gpio86","gpio30";
		};
	};

	cam_sensor_rear_suspend: cam_sensor_rear_suspend{
		mux {
			pins = "gpio86","gpio30";
		};

		config {
			pins = "gpio86","gpio30";
		};
	};
};
// msm8996-pinctrl.dtsi end

// msm8996-regulator.dtsi start
&pm8994_l6 {
	regulator-min-microvolt = <1800000>;
	regulator-max-microvolt = <1800000>;
	qcom,init-voltage = <1800000>;
};

&pm8994_l27 {
	regulator-min-microvolt = <1200000>;
	regulator-max-microvolt = <1200000>;
	qcom,init-voltage = <1200000>;
};

&soc {
	disp_vddts_vreg: disp_vddts_vreg {
		compatible = "regulator-fixed";
		regulator-name = "disp_vddts_vreg";
		startup-delay-us = <4000>;
		enable-active-high;
		gpio = <&tlmm 73 0>;
	};

	disp_vddr_vreg: disp_vddr_vreg1_6 {
		compatible = "regulator-fixed";
		regulator-name = "disp_vddr_vreg";
		startup-delay-us = <4000>;
		enable-active-high;
		regulator-boot-on;
		gpio = <&tlmm 40 0>;
	};
};
// msm8996-regulator.dtsi end

// msm8996.dtsi start
/ {
	aliases {
		i2c3 = &i2c_3;
		i2c9 = &i2c_9;
		/delete-property/ spi9;
		/delete-property/ spi10;
		/delete-property/ spi12;
	};

	reserved-memory {
		removed_regions: removed_regions@85800000 {
			compatible = "removed-dma-pool";
			no-map;
			reg = <0x0 0x85800000 0x0 0x4400000>;
		};

		/delete-node/ peripheral_region@8ea00000;
		peripheral_mem: peripheral_region@8fe00000 {
			compatible = "removed-dma-pool";
			no-map;
			reg = <0x0 0x8fe00000 0x0 0x2b00000>;
		};

		/delete-node/ modem_region@88800000;
		modem_mem: modem_region@89c00000 {
			compatible = "removed-dma-pool";
			no-map;
			reg = <0x0 0x89c00000 0x0 0x6200000>;
		};
	};
};

&soc {
	/delete-node/ uart@7571000;
	/delete-node/ uart@7574000;
	/delete-node/ spi@75B7000;
	/delete-node/ spi@75B8000;

	i2c_3: i2c@7577000 { /* BLSP1 QUP6 */
		compatible = "qcom,i2c-msm-v2";
		#address-cells = <1>;
		#size-cells = <0>;
		reg-names = "qup_phys_addr";
		reg = <0x7577000 0x1000>;
		interrupt-names = "qup_irq";
		interrupts = <0 97 0>;
		dmas = <&dma_blsp1 16 32 0x20000020 0x20>,
			<&dma_blsp1 17 32 0x20000020 0x20>;
		dma-names = "tx", "rx";
		qcom,master-id = <86>;
		qcom,clk-freq-out = <400000>;
		qcom,clk-freq-in  = <19200000>;
		clock-names = "iface_clk", "core_clk";
		clocks = <&clock_gcc clk_gcc_blsp1_ahb_clk>,
			 <&clock_gcc clk_gcc_blsp1_qup6_i2c_apps_clk>;
		pinctrl-names = "i2c_active", "i2c_sleep";
		pinctrl-0 = <&i2c_3_active>;
		pinctrl-1 = <&i2c_3_sleep>;
	};

	i2c_9: i2c@75b7000 { /* BLSP2 QUP3 */
		compatible = "qcom,i2c-msm-v2";
		#address-cells = <1>;
		#size-cells = <0>;
		reg-names = "qup_phys_addr";
		reg = <0x75b7000 0x1000>;
		interrupt-names = "qup_irq";
		interrupts = <0 103 0>;
		dmas = <&dma_blsp2 16 32 0x20000020 0x20>,
			<&dma_blsp2 17 32 0x20000020 0x20>;
		dma-names = "tx", "rx";
		qcom,disable-dma;
		qcom,master-id = <84>;
		qcom,clk-freq-out = <400000>;
		qcom,clk-freq-in  = <19200000>;
		qcom,noise-rjct-scl = <3>;
		qcom,noise-rjct-sda = <3>;
		clock-names = "iface_clk", "core_clk";
		clocks = <&clock_gcc clk_gcc_blsp2_ahb_clk>,
			 <&clock_gcc clk_gcc_blsp2_qup3_i2c_apps_clk>;
		pinctrl-names = "i2c_active", "i2c_sleep";
		pinctrl-0 = <&i2c_9_active>;
		pinctrl-1 = <&i2c_9_sleep>;
	};

	sn_fuse: snfuse@0x74138 {
		compatible = "qcom,sn-fuse";
		reg = <0x74138 0x4>;
		reg-names = "sn-base";
	};

	qcom,sensor-information {
		sensor_information36: qcom,sensor-information-36 {
			qcom,sensor-type = "adc";
			qcom,sensor-name = "xo_therm_buf";
		};
		sensor_information37: qcom,sensor-information-37 {
			qcom,sensor-type = "adc";
			qcom,sensor-name = "battery";
		};
	};

	qcom,bcl {
		qcom,bcl-soc-hotplug-list = <&CPU3>;
		qcom,ibat-monitor {
			qcom,soc-low-threshold = <5>;
		};
	};

	/delete-node/ qcom,msm-dai-mi2s;
	qcom,msm-dai-mi2s {
		compatible = "qcom,msm-dai-mi2s";
		dai_pri_mi2s: qcom,msm-dai-q6-mi2s-prim {
			compatible = "qcom,msm-dai-q6-mi2s";
			qcom,msm-dai-q6-mi2s-dev-id = <0>;
			qcom,msm-mi2s-rx-lines = <1>; /* SD0 (1 << 0) */
			qcom,msm-mi2s-tx-lines = <2>; /* SD1 (1 << 1) */
			qcom,msm-mi2s-slave = <0>;
			qcom,msm-mi2s-ext-mclk = <0>;
		};

		dai_sec_mi2s: qcom,msm-dai-q6-mi2s-sec {
			compatible = "qcom,msm-dai-q6-mi2s";
			qcom,msm-dai-q6-mi2s-dev-id = <1>;
			qcom,msm-mi2s-rx-lines = <3>; /* SD0 (1 << 0) | SD1 (1 << 1) */
			qcom,msm-mi2s-tx-lines = <0>; /* None */
			qcom,msm-mi2s-slave = <1>;
			qcom,msm-mi2s-ext-mclk = <0>;
		};

		dai_tert_mi2s: qcom,msm-dai-q6-mi2s-tert {
			compatible = "qcom,msm-dai-q6-mi2s";
			qcom,msm-dai-q6-mi2s-dev-id = <2>;
			qcom,msm-mi2s-rx-lines = <2>;
			qcom,msm-mi2s-tx-lines = <1>;
		};

		dai_quat_mi2s: qcom,msm-dai-q6-mi2s-quat {
			compatible = "qcom,msm-dai-q6-mi2s";
			qcom,msm-dai-q6-mi2s-dev-id = <3>;
			qcom,msm-mi2s-rx-lines = <1>; /* SD0 (1 << 0) */
			qcom,msm-mi2s-tx-lines = <2>; /* SD1 (1 << 1) */
			qcom,msm-mi2s-slave = <0>;
			qcom,msm-mi2s-ext-mclk = <0>;
			pinctrl-names = "default", "idle";
			pinctrl-0 = <&quat_mi2s_active &quat_mi2s_sd0_active &quat_mi2s_sd1_active>;
			pinctrl-1 = <&quat_mi2s_sleep &quat_mi2s_sd0_sleep &quat_mi2s_sd1_sleep>;
		};
	};
};

&slim_msm {
	tasha_codec {
		qcom,cdc-micbias1-mv = <2750>;
		qcom,cdc-micbias2-mv = <2700>;
		qcom,cdc-micbias3-mv = <2750>;
		qcom,cdc-micbias4-mv = <2750>;

		/delete-node/ swr_master;
	};
};

&wdog {
	qcom,bark-time = <20000>;
	qcom,pet-time = <15000>;
};

&pcm1 {
	/delete-property/ qcom,latency-level;
};

&pcm2 {
	/delete-property/ qcom,latency-level;
};

&qcom_seecom {
	reg = <0x86600000 0x3600000>;
};

&qusb_phy0 {
	reg = <0x07411000 0x180>,
		<0x06af8800 0x400>,
		<0x00388018 0x4>;
	reg-names = "qusb_phy_base", "qscratch_base", "ref_clk_addr";
	qcom,qusb-phy-init-seq = <0x38 0x80
				0x7b 0x84
				0x93 0x88
				0xcf 0x8c
				0x30 0x8
				0x79 0xc
				0x21 0x10
				0x14 0x9c
				0x9f 0x1c
				0x0 0x18>;
};

&qusb_phy1 {
	reg = <0x07412000 0x180>,
		<0x076f8800 0x400>,
		<0x00388014 0x4>;
	reg-names = "qusb_phy_base", "qscratch_base", "ref_clk_addr";
	qcom,qusb-phy-init-seq = <0x38 0x80
				0x7b 0x84
				0x93 0x88
				0xcf 0x8c
				0x30 0x8
				0x79 0xc
				0x21 0x10
				0x14 0x9c
				0x9f 0x1c
				0x0 0x18>;
};
// msm8996.dtsi end
